AUTOSAR XML (schema 4-2-1)
package /MyDataTypes
  base type myuint8: category=FIXED_LENGTH, base-type-size=8, base-type-encoding=NONE, native-declaration=unsigned char
  impl type myuint8: category=VALUE, base-type=myuint8, range phys 0..255, raw 0..255
package /Interfaces
  sender receiver interface IF_SR_DoorLock
    data DoorState: type=myuint8
  client server interface IF_CS_LED
    operation LED_Switch: possible-error=[E_OK, E_NOT_OK]
      arg LedState: type=myuint8, direction=IN
    error E_OK: error-code=0
    error E_NOT_OK: error-code=1
package /SWCs
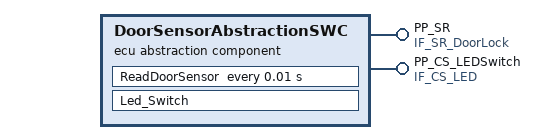
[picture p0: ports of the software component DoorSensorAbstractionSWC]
  ecu abstraction sw component type DoorSensorAbstractionSWC
    provide port PP_SR: provided-interface=IF_SR_DoorLock
    provide port PP_CS_LEDSwitch: provided-interface=IF_CS_LED
    behavior IB_DoorSensorAbstractionSWC
      timing event TE_10ms: start-on-event=ReadDoorSensor, period=0.01
      operation invoked event OIE_LedSwitch: start-on-event=Led_Switch, operation=PP_CS_LEDSwitch.LED_Switch
      runnable ReadDoorSensor: symbol=ReadDoorSensor_Runnable
        data-write-access:
          access DA_DoorState: accessed-variable=PP_SR.DoorState
      runnable Led_Switch: symbol=Led_Switch_Runnable
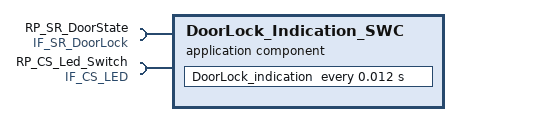
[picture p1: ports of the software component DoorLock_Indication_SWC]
  application sw component type DoorLock_Indication_SWC
    require port RP_SR_DoorState: required-interface=IF_SR_DoorLock
    require port RP_CS_Led_Switch: required-interface=IF_CS_LED
    behavior IB_DoorLock_Indication_SWC
      timing event TE_12ms: start-on-event=DoorLock_indication, period=0.012
      runnable DoorLock_indication: symbol=DoorLock_indication_runnable
        data-read-access:
          access DA_read: accessed-variable=RP_SR_DoorState.DoorState
        sync call ServerCall: operation=RP_CS_Led_Switch.LED_Switch
package /Composition
  composition sw component type Composite_DoorLock_SWC
    component DoorSensorAbstractionSWC: type=DoorSensorAbstractionSWC
    component DoorLock_Indication_SWC: type=DoorLock_Indication_SWC
    connect DoorSensorAbstractionSWC.PP_SR -> DoorLock_Indication_SWC.RP_SR_DoorState
    connect DoorSensorAbstractionSWC.PP_CS_LEDSwitch -> DoorLock_Indication_SWC.RP_CS_Led_Switch
